# ESP32C5_RADIO register map
Vendor: Espressif; Series: ESP32-C5; File version: 0.1
Registers are 32-bit, read-write, no defined reset value unless marked. A register's access mark holds for its fields unless they carry their own. Offsets are from the block's base; [hi:lo] are bit positions; 'fields as' and 'values as' point back to an identical list.

## MODEM_WIFI_MAC_OBSERVED (part 2 of 2) — Sparse source-qualified word views in the existing owned MMIO aperture; individual meanings and side effects remain unknown.
Base 0x600A4000
0x814 WORD_0814_OPAQUE — Opaque: meaning not established. Aligned 32-bit bus view explicitly addressed by the cited vendor source. No reset or hardware write effect is established.
  [31:0] BITS_0_31_OPAQUE — Opaque: meaning not established. Observed source use; the individual hardware meaning is unknown.
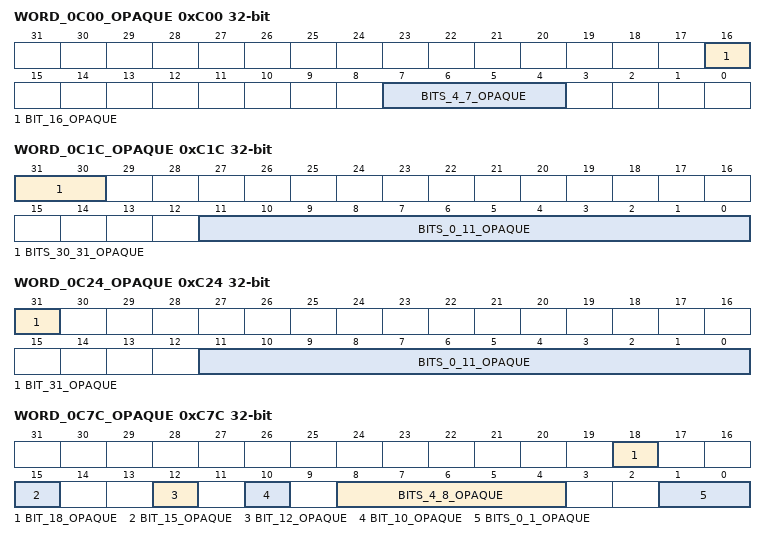
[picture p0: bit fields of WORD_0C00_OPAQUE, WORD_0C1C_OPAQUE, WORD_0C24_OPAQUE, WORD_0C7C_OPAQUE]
0xC00 WORD_0C00_OPAQUE — Opaque: meaning not established. Aligned 32-bit bus view explicitly addressed by the cited vendor source. No reset or hardware write effect is established.
  [16] BIT_16_OPAQUE — Opaque: meaning not established. Observed source use; the individual hardware meaning is unknown.
  [7:4] BITS_4_7_OPAQUE — Opaque: meaning not established. Observed source use; the individual hardware meaning is unknown.
0xC1C WORD_0C1C_OPAQUE — Opaque: meaning not established. Aligned 32-bit bus view explicitly addressed by the cited vendor source. No reset or hardware write effect is established.
  [31:30] BITS_30_31_OPAQUE — Opaque: meaning not established. Observed source use; the individual hardware meaning is unknown.
  [11:0] BITS_0_11_OPAQUE — Opaque: meaning not established. Observed source use; the individual hardware meaning is unknown.
0xC20 WORD_0C20_OPAQUE — Opaque: meaning not established. Aligned 32-bit bus view explicitly addressed by the cited vendor source. No reset or hardware write effect is established.
  [11:0] BITS_0_11_OPAQUE — Opaque: meaning not established. Observed source use; the individual hardware meaning is unknown.
0xC24 WORD_0C24_OPAQUE — Opaque: meaning not established. Aligned 32-bit bus view explicitly addressed by the cited vendor source. No reset or hardware write effect is established.
  [31] BIT_31_OPAQUE — Opaque: meaning not established. Observed source use; the individual hardware meaning is unknown.
  [11:0] BITS_0_11_OPAQUE — Opaque: meaning not established. Observed source use; the individual hardware meaning is unknown.
0xC2C WORD_0C2C_OPAQUE — Opaque: meaning not established. Aligned 32-bit bus view explicitly addressed by the cited vendor source. No reset or hardware write effect is established.
  [12] BIT_12_OPAQUE — Opaque: meaning not established. Observed source use; the individual hardware meaning is unknown.
0xC34 WORD_0C34_OPAQUE ro — Opaque: meaning not established. Aligned 32-bit bus view explicitly addressed by the cited vendor source. No reset or hardware write effect is established.
  fields as WORD_0C2C_OPAQUE
0xC38 WORD_0C38_OPAQUE — Opaque: meaning not established. Aligned 32-bit bus view explicitly addressed by the cited vendor source. No reset or hardware write effect is established.
  fields as WORD_0C2C_OPAQUE
0xC50 WORD_0C50_OPAQUE — Opaque: meaning not established. Aligned 32-bit bus view explicitly addressed by the cited vendor source. No reset or hardware write effect is established.
  [15:0] BITS_0_15_OPAQUE — Opaque: meaning not established. Observed source use; the individual hardware meaning is unknown.
0xC54 WORD_0C54_OPAQUE — Opaque: meaning not established. Aligned 32-bit bus view explicitly addressed by the cited vendor source. No reset or hardware write effect is established.
  [31:10] BITS_10_31_OPAQUE — Opaque: meaning not established. Observed source use; the individual hardware meaning is unknown.
0xC58 WORD_0C58_OPAQUE — Opaque: meaning not established. Aligned 32-bit bus view explicitly addressed by the cited vendor source. No reset or hardware write effect is established.
  fields as WORD_0814_OPAQUE
0xC60 WORD_0C60_OPAQUE — Opaque: meaning not established. Aligned 32-bit bus view explicitly addressed by the cited vendor source. No reset or hardware write effect is established.
  [31:16] BITS_16_31_OPAQUE — Opaque: meaning not established. Observed source use; the individual hardware meaning is unknown.
0xC64 WORD_0C64_OPAQUE ro — Opaque: meaning not established. Aligned 32-bit bus view explicitly addressed by the cited vendor source. No reset or hardware write effect is established.
  fields as WORD_0C60_OPAQUE
0xC70 WORD_0C70_OPAQUE ro — Opaque: meaning not established. Aligned 32-bit bus view explicitly addressed by the cited vendor source. No reset or hardware write effect is established.
  [31:20] BITS_20_31_OPAQUE — Opaque: meaning not established. Observed source use; the individual hardware meaning is unknown.
0xC74 WORD_0C74_OPAQUE ro — Opaque: meaning not established. Aligned 32-bit bus view explicitly addressed by the cited vendor source. No reset or hardware write effect is established.
  [31:28] BITS_28_31_OPAQUE — Opaque: meaning not established. Observed source use; the individual hardware meaning is unknown.
0xC78 WORD_0C78_OPAQUE — Opaque: meaning not established. Aligned 32-bit bus view explicitly addressed by the cited vendor source. No reset or hardware write effect is established.
  fields as WORD_0814_OPAQUE
0xC7C WORD_0C7C_OPAQUE — Opaque: meaning not established. Aligned 32-bit bus view explicitly addressed by the cited vendor source. No reset or hardware write effect is established.
  [18] BIT_18_OPAQUE — Opaque: meaning not established. Observed source use; the individual hardware meaning is unknown.
  [15] BIT_15_OPAQUE — Opaque: meaning not established. Observed source use; the individual hardware meaning is unknown.
  [12] BIT_12_OPAQUE — Opaque: meaning not established. Observed source use; the individual hardware meaning is unknown.
  [10] BIT_10_OPAQUE — Opaque: meaning not established. Observed source use; the individual hardware meaning is unknown.
  [8:4] BITS_4_8_OPAQUE — Opaque: meaning not established. Observed source use; the individual hardware meaning is unknown.
  [1:0] BITS_0_1_OPAQUE — Opaque: meaning not established. Observed source use; the individual hardware meaning is unknown.
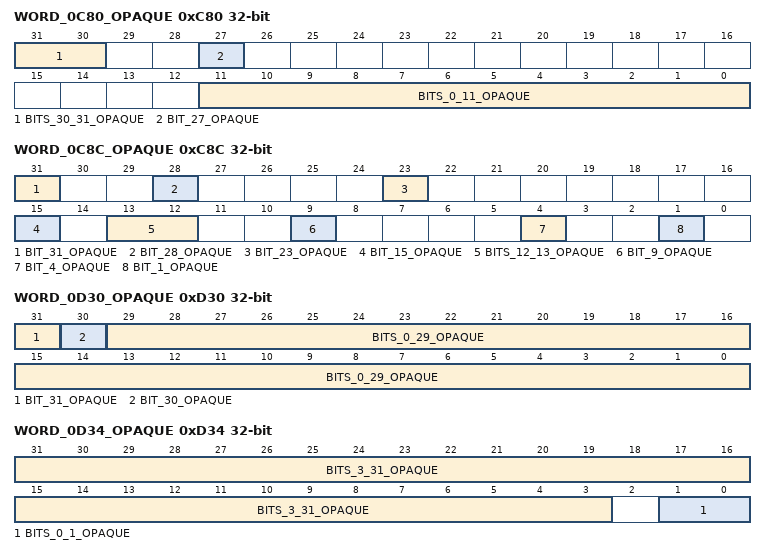
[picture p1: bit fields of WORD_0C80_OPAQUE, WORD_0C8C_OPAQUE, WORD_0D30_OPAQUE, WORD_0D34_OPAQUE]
0xC80 WORD_0C80_OPAQUE — Opaque: meaning not established. Aligned 32-bit bus view explicitly addressed by the cited vendor source. No reset or hardware write effect is established.
  [31:30] BITS_30_31_OPAQUE — Opaque: meaning not established. Observed source use; the individual hardware meaning is unknown.
  [27] BIT_27_OPAQUE — Opaque: meaning not established. Observed source use; the individual hardware meaning is unknown.
  [11:0] BITS_0_11_OPAQUE — Opaque: meaning not established. Observed source use; the individual hardware meaning is unknown.
0xC84 WORD_0C84_OPAQUE — Opaque: meaning not established. Aligned 32-bit bus view explicitly addressed by the cited vendor source. No reset or hardware write effect is established.
  [31:18] BITS_18_31_OPAQUE — Opaque: meaning not established. Observed source use; the individual hardware meaning is unknown.
0xC88 WORD_0C88_OPAQUE — Opaque: meaning not established. Aligned 32-bit bus view explicitly addressed by the cited vendor source. No reset or hardware write effect is established.
  [1:0] BITS_0_1_OPAQUE — Opaque: meaning not established. Observed source use; the individual hardware meaning is unknown.
0xC8C WORD_0C8C_OPAQUE — Opaque: meaning not established. Aligned 32-bit bus view explicitly addressed by the cited vendor source. No reset or hardware write effect is established.
  [31] BIT_31_OPAQUE — Opaque: meaning not established. Observed source use; the individual hardware meaning is unknown.
  [28] BIT_28_OPAQUE — Opaque: meaning not established. Observed source use; the individual hardware meaning is unknown.
  [23] BIT_23_OPAQUE — Opaque: meaning not established. Observed source use; the individual hardware meaning is unknown.
  [15] BIT_15_OPAQUE — Opaque: meaning not established. Observed source use; the individual hardware meaning is unknown.
  [13:12] BITS_12_13_OPAQUE — Opaque: meaning not established. Observed source use; the individual hardware meaning is unknown.
  [9] BIT_9_OPAQUE — Opaque: meaning not established. Observed source use; the individual hardware meaning is unknown.
  [4] BIT_4_OPAQUE — Opaque: meaning not established. Observed source use; the individual hardware meaning is unknown.
  [1] BIT_1_OPAQUE — Opaque: meaning not established. Observed source use; the individual hardware meaning is unknown.
0xC90 WORD_0C90_OPAQUE — Opaque: meaning not established. Aligned 32-bit bus view explicitly addressed by the cited vendor source. No reset or hardware write effect is established.
  fields as WORD_0814_OPAQUE
0xC94 WORD_0C94_OPAQUE — Opaque: meaning not established. Aligned source-qualified 32-bit bus view in the existing owned aperture. No reset, safe transaction or read safety is established.
  [7:0] BITS_0_7_OPAQUE — Opaque: meaning not established. Observed source use; the individual hardware meaning is unknown.
0xC98 WORD_0C98_OPAQUE — Opaque: meaning not established. Aligned 32-bit bus view explicitly addressed by the cited vendor source. No reset or hardware write effect is established.
  [3:2] BITS_2_3_OPAQUE — Opaque: meaning not established. Observed source use; the individual hardware meaning is unknown.
0xC9C WORD_0C9C_OPAQUE — Opaque: meaning not established. Aligned 32-bit bus view explicitly addressed by the cited vendor source. No reset or hardware write effect is established.
  fields as WORD_0814_OPAQUE
0xCA0 WORD_0CA0_OPAQUE — Opaque: meaning not established. Aligned 32-bit bus view explicitly addressed by the cited vendor source. No reset or hardware write effect is established.
  fields as WORD_0814_OPAQUE
0xCA4 WORD_0CA4_OPAQUE — Opaque: meaning not established. Aligned 32-bit bus view explicitly addressed by the cited vendor source. No reset or hardware write effect is established.
  fields as WORD_0C94_OPAQUE
0xCA8 WORD_0CA8_OPAQUE — Opaque: meaning not established. Aligned 32-bit bus view explicitly addressed by the cited vendor source. No reset or hardware write effect is established.
  fields as WORD_0814_OPAQUE
0xCBC WORD_0CBC_OPAQUE — Opaque: meaning not established. Aligned 32-bit bus view explicitly addressed by the cited vendor source. No reset or hardware write effect is established.
  [31] BIT_31_OPAQUE — Opaque: meaning not established. Observed source use; the individual hardware meaning is unknown.
0xCC4 WORD_0CC4_OPAQUE — Opaque: meaning not established. Aligned source-qualified 32-bit bus view in the existing owned aperture. No reset, safe transaction or read safety is established.
  [2] BIT_2_OPAQUE — Opaque: meaning not established. Observed source use; the individual hardware meaning is unknown.
0xCD4 WORD_0CD4_OPAQUE — Opaque: meaning not established. Aligned 32-bit bus view explicitly addressed by the cited vendor source. No reset or hardware write effect is established.
  fields as WORD_0CC4_OPAQUE
0xCE4 WORD_0CE4_OPAQUE — Opaque: meaning not established. Aligned 32-bit bus view explicitly addressed by the cited vendor source. No reset or hardware write effect is established.
  fields as WORD_0CC4_OPAQUE
0xCF8 WORD_0CF8_OPAQUE ro — Opaque: meaning not established. Aligned 32-bit bus view explicitly addressed by the cited vendor source. No reset or hardware write effect is established.
  fields as WORD_0814_OPAQUE
0xD08 WORD_0D08_OPAQUE ro — Opaque: meaning not established. Aligned 32-bit bus view explicitly addressed by the cited vendor source. No reset or hardware write effect is established.
  fields as WORD_0814_OPAQUE
0xD18 WORD_0D18_OPAQUE ro — Opaque: meaning not established. Aligned 32-bit bus view explicitly addressed by the cited vendor source. No reset or hardware write effect is established.
  fields as WORD_0814_OPAQUE
0xD28 WORD_0D28_OPAQUE ro — Opaque: meaning not established. Aligned 32-bit bus view explicitly addressed by the cited vendor source. No reset or hardware write effect is established.
  fields as WORD_0814_OPAQUE
0xD30 WORD_0D30_OPAQUE — Opaque: meaning not established. Aligned 32-bit bus view explicitly addressed by the cited vendor source. No reset or hardware write effect is established.
  [31] BIT_31_OPAQUE — Opaque: meaning not established. Observed source use; the individual hardware meaning is unknown.
  [30] BIT_30_OPAQUE — Opaque: meaning not established. Observed source use; the individual hardware meaning is unknown.
  [29:0] BITS_0_29_OPAQUE — Opaque: meaning not established. Observed source use; the individual hardware meaning is unknown.
0xD34 WORD_0D34_OPAQUE — Opaque: meaning not established. Aligned 32-bit bus view explicitly addressed by the cited vendor source. No reset or hardware write effect is established.
  [31:3] BITS_3_31_OPAQUE — Opaque: meaning not established. Observed source use; the individual hardware meaning is unknown.
  [1:0] BITS_0_1_OPAQUE — Opaque: meaning not established. Observed source use; the individual hardware meaning is unknown.
0xD38 WORD_0D38_OPAQUE ro — Opaque: meaning not established. Aligned 32-bit bus view explicitly addressed by the cited vendor source. No reset or hardware write effect is established.
  fields as WORD_0814_OPAQUE
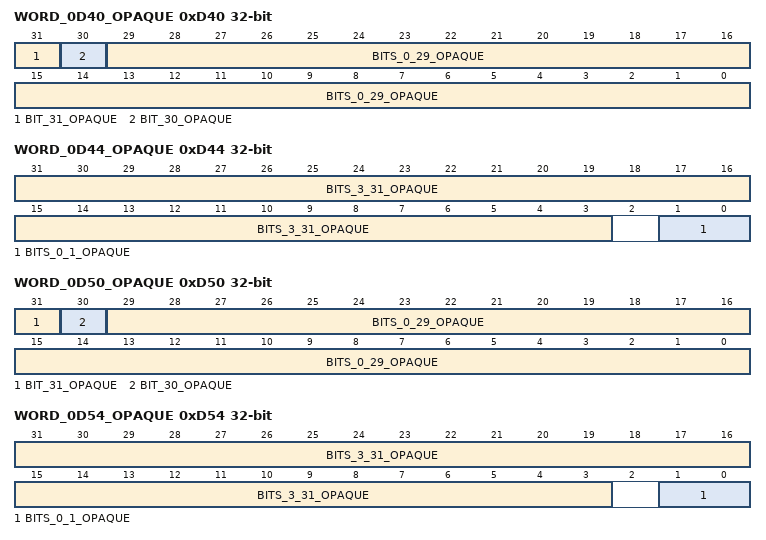
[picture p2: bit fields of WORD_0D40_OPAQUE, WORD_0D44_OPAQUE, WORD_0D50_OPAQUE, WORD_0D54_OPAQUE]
0xD40 WORD_0D40_OPAQUE — Opaque: meaning not established. Aligned 32-bit bus view explicitly addressed by the cited vendor source. No reset or hardware write effect is established.
  fields as WORD_0D30_OPAQUE
0xD44 WORD_0D44_OPAQUE — Opaque: meaning not established. Aligned 32-bit bus view explicitly addressed by the cited vendor source. No reset or hardware write effect is established.
  fields as WORD_0D34_OPAQUE
0xD48 WORD_0D48_OPAQUE ro — Opaque: meaning not established. Aligned 32-bit bus view explicitly addressed by the cited vendor source. No reset or hardware write effect is established.
  fields as WORD_0814_OPAQUE
0xD50 WORD_0D50_OPAQUE — Opaque: meaning not established. Aligned 32-bit bus view explicitly addressed by the cited vendor source. No reset or hardware write effect is established.
  fields as WORD_0D30_OPAQUE
0xD54 WORD_0D54_OPAQUE — Opaque: meaning not established. Aligned 32-bit bus view explicitly addressed by the cited vendor source. No reset or hardware write effect is established.
  fields as WORD_0D34_OPAQUE
0xD58 WORD_0D58_OPAQUE ro — Opaque: meaning not established. Aligned 32-bit bus view explicitly addressed by the cited vendor source. No reset or hardware write effect is established.
  fields as WORD_0814_OPAQUE
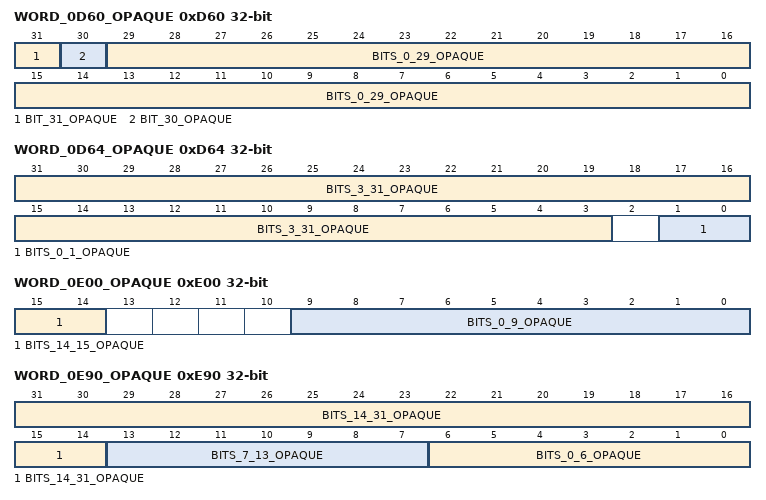
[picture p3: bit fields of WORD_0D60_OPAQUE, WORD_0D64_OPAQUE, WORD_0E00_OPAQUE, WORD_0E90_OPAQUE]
0xD60 WORD_0D60_OPAQUE — Opaque: meaning not established. Aligned 32-bit bus view explicitly addressed by the cited vendor source. No reset or hardware write effect is established.
  fields as WORD_0D30_OPAQUE
0xD64 WORD_0D64_OPAQUE — Opaque: meaning not established. Aligned 32-bit bus view explicitly addressed by the cited vendor source. No reset or hardware write effect is established.
  fields as WORD_0D34_OPAQUE
0xD68 WORD_0D68_OPAQUE — Opaque: meaning not established. Aligned 32-bit bus view explicitly addressed by the cited vendor source. No reset or hardware write effect is established.
  fields as WORD_0814_OPAQUE
0xD74 WORD_0D74_OPAQUE — Opaque: meaning not established. Aligned source-qualified 32-bit bus view in the existing owned aperture. No reset, safe transaction or read safety is established.
  [19:0] BITS_0_19_OPAQUE — Opaque: meaning not established. Observed source use; the individual hardware meaning is unknown.
0xD7C WORD_0D7C_OPAQUE — Opaque: meaning not established. Aligned source-qualified 32-bit bus view in the existing owned aperture. No reset, safe transaction or read safety is established.
  fields as WORD_0D74_OPAQUE
0xD84 WORD_0D84_OPAQUE — Opaque: meaning not established. Aligned source-qualified 32-bit bus view in the existing owned aperture. No reset, safe transaction or read safety is established.
  fields as WORD_0D74_OPAQUE
0xD8C WORD_0D8C_OPAQUE — Opaque: meaning not established. Aligned source-qualified 32-bit bus view in the existing owned aperture. No reset, safe transaction or read safety is established.
  fields as WORD_0D74_OPAQUE
0xDB4 WORD_0DB4_OPAQUE — Opaque: meaning not established. Aligned 32-bit bus view explicitly addressed by the cited vendor source. No reset or hardware write effect is established.
  fields as WORD_0814_OPAQUE
0xDB8 WORD_0DB8_OPAQUE — Opaque: meaning not established. Aligned 32-bit bus view explicitly addressed by the cited vendor source. No reset or hardware write effect is established.
  fields as WORD_0814_OPAQUE
0xDBC WORD_0DBC_OPAQUE — Opaque: meaning not established. Aligned 32-bit bus view explicitly addressed by the cited vendor source. No reset or hardware write effect is established.
  fields as WORD_0814_OPAQUE
0xDC0 WORD_0DC0_OPAQUE — Opaque: meaning not established. Aligned 32-bit bus view explicitly addressed by the cited vendor source. No reset or hardware write effect is established.
  fields as WORD_0814_OPAQUE
0xDC4 WORD_0DC4_OPAQUE — Opaque: meaning not established. Aligned 32-bit bus view explicitly addressed by the cited vendor source. No reset or hardware write effect is established.
  fields as WORD_0814_OPAQUE
0xDD0 WORD_0DD0_OPAQUE — Opaque: meaning not established. Aligned 32-bit bus view explicitly addressed by the cited vendor source. No reset or hardware write effect is established.
  fields as WORD_0814_OPAQUE
0xDD4 WORD_0DD4_OPAQUE — Opaque: meaning not established. Aligned 32-bit bus view explicitly addressed by the cited vendor source. No reset or hardware write effect is established.
  fields as WORD_0814_OPAQUE
0xDD8 WORD_0DD8_OPAQUE — Opaque: meaning not established. Aligned 32-bit bus view explicitly addressed by the cited vendor source. No reset or hardware write effect is established.
  [5:0] BITS_0_5_OPAQUE — Opaque: meaning not established. Observed source use; the individual hardware meaning is unknown.
0xDDC WORD_0DDC_OPAQUE — Opaque: meaning not established. Aligned 32-bit bus view explicitly addressed by the cited vendor source. No reset or hardware write effect is established.
  fields as WORD_0C88_OPAQUE
0xDE0 WORD_0DE0_OPAQUE — Opaque: meaning not established. Aligned 32-bit bus view explicitly addressed by the cited vendor source. No reset or hardware write effect is established.
  fields as WORD_0C70_OPAQUE
0xDEC WORD_0DEC_OPAQUE — Opaque: meaning not established. Aligned source-qualified 32-bit bus view in the existing owned aperture. No reset, safe transaction or read safety is established.
  [0] BIT_0_OPAQUE — Opaque: meaning not established. Observed source use; the individual hardware meaning is unknown.
0xDF0 WORD_0DF0_OPAQUE — Opaque: meaning not established. Aligned 32-bit bus view explicitly addressed by the cited vendor source. No reset or hardware write effect is established.
  fields as WORD_0814_OPAQUE
0xDF4 WORD_0DF4_OPAQUE — Opaque: meaning not established. Aligned source-qualified 32-bit bus view in the existing owned aperture. No reset, safe transaction or read safety is established.
  fields as WORD_0DEC_OPAQUE
0xDF8 WORD_0DF8_OPAQUE — Opaque: meaning not established. Aligned 32-bit bus view explicitly addressed by the cited vendor source. No reset or hardware write effect is established.
  fields as WORD_0814_OPAQUE
0xDFC WORD_0DFC_OPAQUE — Opaque: meaning not established. Aligned 32-bit bus view explicitly addressed by the cited vendor source. No reset or hardware write effect is established.
  fields as WORD_0814_OPAQUE
0xE00 WORD_0E00_OPAQUE — Opaque: meaning not established. Aligned 32-bit bus view explicitly addressed by the cited vendor source. No reset or hardware write effect is established.
  [15:14] BITS_14_15_OPAQUE — Opaque: meaning not established. Observed source use; the individual hardware meaning is unknown.
  [9:0] BITS_0_9_OPAQUE — Opaque: meaning not established. Observed source use; the individual hardware meaning is unknown.
0xE14 WORD_0E14_OPAQUE ro — Opaque: meaning not established. Aligned 32-bit bus view explicitly addressed by the cited vendor source. No reset or hardware write effect is established.
  fields as WORD_0814_OPAQUE
0xE18 WORD_0E18_OPAQUE ro — Opaque: meaning not established. Aligned 32-bit bus view explicitly addressed by the cited vendor source. No reset or hardware write effect is established.
  fields as WORD_0814_OPAQUE
0xE1C WORD_0E1C_OPAQUE ro — Opaque: meaning not established. Aligned 32-bit bus view explicitly addressed by the cited vendor source. No reset or hardware write effect is established.
  fields as WORD_0814_OPAQUE
0xE24 WORD_0E24_OPAQUE — Opaque: meaning not established. Aligned 32-bit bus view explicitly addressed by the cited vendor source. No reset or hardware write effect is established.
  fields as WORD_0CBC_OPAQUE
0xE2C WORD_0E2C_OPAQUE ro — Opaque: meaning not established. Aligned 32-bit bus view explicitly addressed by the cited vendor source. No reset or hardware write effect is established.
  fields as WORD_0814_OPAQUE
0xE30 WORD_0E30_OPAQUE ro — Opaque: meaning not established. Aligned 32-bit bus view explicitly addressed by the cited vendor source. No reset or hardware write effect is established.
  fields as WORD_0814_OPAQUE
0xE38 WORD_0E38_OPAQUE — Opaque: meaning not established. Aligned 32-bit bus view explicitly addressed by the cited vendor source. No reset or hardware write effect is established.
  [8:0] BITS_0_8_OPAQUE — Opaque: meaning not established. Observed source use; the individual hardware meaning is unknown.
0xE8C WORD_0E8C_OPAQUE ro — Opaque: meaning not established. Aligned 32-bit bus view explicitly addressed by the cited vendor source. No reset or hardware write effect is established.
  fields as WORD_0814_OPAQUE
0xE90 WORD_0E90_OPAQUE ro — Opaque: meaning not established. Aligned 32-bit bus view explicitly addressed by the cited vendor source. No reset or hardware write effect is established.
  [31:14] BITS_14_31_OPAQUE — Opaque: meaning not established. Observed source use; the individual hardware meaning is unknown.
  [13:7] BITS_7_13_OPAQUE — Opaque: meaning not established. Observed source use; the individual hardware meaning is unknown.
  [6:0] BITS_0_6_OPAQUE — Opaque: meaning not established. Observed source use; the individual hardware meaning is unknown.
0xE94 WORD_0E94_OPAQUE ro — Opaque: meaning not established. Aligned 32-bit bus view explicitly addressed by the cited vendor source. No reset or hardware write effect is established.
  fields as WORD_0814_OPAQUE
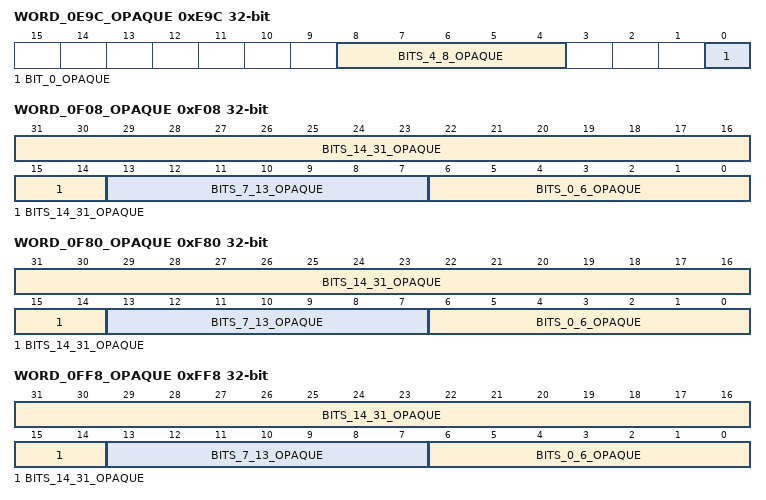
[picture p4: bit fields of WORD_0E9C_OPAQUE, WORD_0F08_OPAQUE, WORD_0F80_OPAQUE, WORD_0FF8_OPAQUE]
0xE9C WORD_0E9C_OPAQUE — Opaque: meaning not established. Aligned 32-bit bus view explicitly addressed by the cited vendor source. No reset or hardware write effect is established.
  [8:4] BITS_4_8_OPAQUE — Opaque: meaning not established. Observed source use; the individual hardware meaning is unknown.
  [0] BIT_0_OPAQUE — Opaque: meaning not established. Observed source use; the individual hardware meaning is unknown.
0xEA0 WORD_0EA0_OPAQUE — Opaque: meaning not established. Aligned 32-bit bus view explicitly addressed by the cited vendor source. No reset or hardware write effect is established.
  [31:5] BITS_5_31_OPAQUE — Opaque: meaning not established. Observed source use; the individual hardware meaning is unknown.
0xEA4 WORD_0EA4_OPAQUE — Opaque: meaning not established. Aligned 32-bit bus view explicitly addressed by the cited vendor source. No reset or hardware write effect is established.
  [24:18] BITS_18_24_OPAQUE — Opaque: meaning not established. Observed source use; the individual hardware meaning is unknown.
0xEAC WORD_0EAC_OPAQUE — Opaque: meaning not established. Aligned 32-bit bus view explicitly addressed by the cited vendor source. No reset or hardware write effect is established.
  fields as WORD_0C20_OPAQUE
0xF04 WORD_0F04_OPAQUE ro — Opaque: meaning not established. Aligned 32-bit bus view explicitly addressed by the cited vendor source. No reset or hardware write effect is established.
  fields as WORD_0814_OPAQUE
0xF08 WORD_0F08_OPAQUE ro — Opaque: meaning not established. Aligned 32-bit bus view explicitly addressed by the cited vendor source. No reset or hardware write effect is established.
  fields as WORD_0E90_OPAQUE
0xF0C WORD_0F0C_OPAQUE ro — Opaque: meaning not established. Aligned 32-bit bus view explicitly addressed by the cited vendor source. No reset or hardware write effect is established.
  fields as WORD_0814_OPAQUE
0xF7C WORD_0F7C_OPAQUE ro — Opaque: meaning not established. Aligned 32-bit bus view explicitly addressed by the cited vendor source. No reset or hardware write effect is established.
  fields as WORD_0814_OPAQUE
0xF80 WORD_0F80_OPAQUE ro — Opaque: meaning not established. Aligned 32-bit bus view explicitly addressed by the cited vendor source. No reset or hardware write effect is established.
  fields as WORD_0E90_OPAQUE
0xF84 WORD_0F84_OPAQUE ro — Opaque: meaning not established. Aligned 32-bit bus view explicitly addressed by the cited vendor source. No reset or hardware write effect is established.
  fields as WORD_0814_OPAQUE
0xFF4 WORD_0FF4_OPAQUE ro — Opaque: meaning not established. Aligned 32-bit bus view explicitly addressed by the cited vendor source. No reset or hardware write effect is established.
  fields as WORD_0814_OPAQUE
0xFF8 WORD_0FF8_OPAQUE ro — Opaque: meaning not established. Aligned 32-bit bus view explicitly addressed by the cited vendor source. No reset or hardware write effect is established.
  fields as WORD_0E90_OPAQUE
0xFFC WORD_0FFC_OPAQUE ro — Opaque: meaning not established. Aligned 32-bit bus view explicitly addressed by the cited vendor source. No reset or hardware write effect is established.
  fields as WORD_0814_OPAQUE
0x106C WORD_106C_OPAQUE ro — Opaque: meaning not established. Aligned 32-bit bus view explicitly addressed by the cited vendor source. No reset or hardware write effect is established.
  fields as WORD_0814_OPAQUE
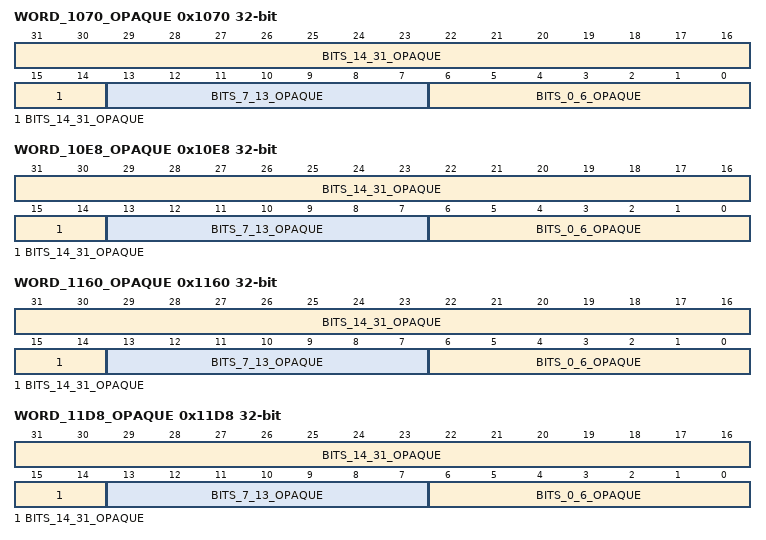
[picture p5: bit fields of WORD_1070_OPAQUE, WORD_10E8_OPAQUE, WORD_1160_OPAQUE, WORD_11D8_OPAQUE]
0x1070 WORD_1070_OPAQUE ro — Opaque: meaning not established. Aligned 32-bit bus view explicitly addressed by the cited vendor source. No reset or hardware write effect is established.
  fields as WORD_0E90_OPAQUE
0x1074 WORD_1074_OPAQUE ro — Opaque: meaning not established. Aligned 32-bit bus view explicitly addressed by the cited vendor source. No reset or hardware write effect is established.
  fields as WORD_0814_OPAQUE
0x10E4 WORD_10E4_OPAQUE ro — Opaque: meaning not established. Aligned 32-bit bus view explicitly addressed by the cited vendor source. No reset or hardware write effect is established.
  fields as WORD_0814_OPAQUE
0x10E8 WORD_10E8_OPAQUE ro — Opaque: meaning not established. Aligned 32-bit bus view explicitly addressed by the cited vendor source. No reset or hardware write effect is established.
  fields as WORD_0E90_OPAQUE
0x10EC WORD_10EC_OPAQUE ro — Opaque: meaning not established. Aligned 32-bit bus view explicitly addressed by the cited vendor source. No reset or hardware write effect is established.
  fields as WORD_0814_OPAQUE
0x115C WORD_115C_OPAQUE ro — Opaque: meaning not established. Aligned 32-bit bus view explicitly addressed by the cited vendor source. No reset or hardware write effect is established.
  fields as WORD_0814_OPAQUE
0x1160 WORD_1160_OPAQUE ro — Opaque: meaning not established. Aligned 32-bit bus view explicitly addressed by the cited vendor source. No reset or hardware write effect is established.
  fields as WORD_0E90_OPAQUE
0x1164 WORD_1164_OPAQUE ro — Opaque: meaning not established. Aligned 32-bit bus view explicitly addressed by the cited vendor source. No reset or hardware write effect is established.
  fields as WORD_0814_OPAQUE
0x11D4 WORD_11D4_OPAQUE ro — Opaque: meaning not established. Aligned 32-bit bus view explicitly addressed by the cited vendor source. No reset or hardware write effect is established.
  fields as WORD_0814_OPAQUE
0x11D8 WORD_11D8_OPAQUE ro — Opaque: meaning not established. Aligned 32-bit bus view explicitly addressed by the cited vendor source. No reset or hardware write effect is established.
  fields as WORD_0E90_OPAQUE
0x11DC WORD_11DC_OPAQUE ro — Opaque: meaning not established. Aligned 32-bit bus view explicitly addressed by the cited vendor source. No reset or hardware write effect is established.
  fields as WORD_0814_OPAQUE
0x124C WORD_124C_OPAQUE ro — Opaque: meaning not established. Aligned 32-bit bus view explicitly addressed by the cited vendor source. No reset or hardware write effect is established.
  fields as WORD_0814_OPAQUE
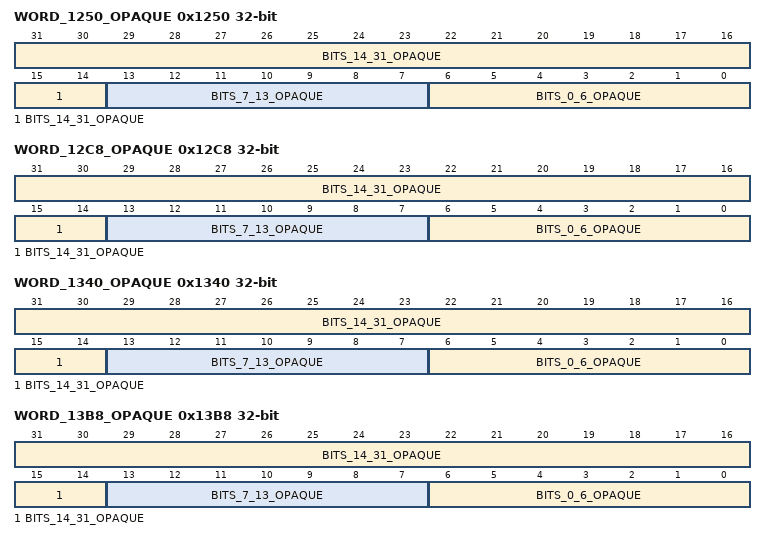
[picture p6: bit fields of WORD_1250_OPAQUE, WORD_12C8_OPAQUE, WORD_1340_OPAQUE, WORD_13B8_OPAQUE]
0x1250 WORD_1250_OPAQUE ro — Opaque: meaning not established. Aligned 32-bit bus view explicitly addressed by the cited vendor source. No reset or hardware write effect is established.
  fields as WORD_0E90_OPAQUE
0x1254 WORD_1254_OPAQUE ro — Opaque: meaning not established. Aligned 32-bit bus view explicitly addressed by the cited vendor source. No reset or hardware write effect is established.
  fields as WORD_0814_OPAQUE
0x12C4 WORD_12C4_OPAQUE ro — Opaque: meaning not established. Aligned 32-bit bus view explicitly addressed by the cited vendor source. No reset or hardware write effect is established.
  fields as WORD_0814_OPAQUE
0x12C8 WORD_12C8_OPAQUE ro — Opaque: meaning not established. Aligned 32-bit bus view explicitly addressed by the cited vendor source. No reset or hardware write effect is established.
  fields as WORD_0E90_OPAQUE
0x12CC WORD_12CC_OPAQUE ro — Opaque: meaning not established. Aligned 32-bit bus view explicitly addressed by the cited vendor source. No reset or hardware write effect is established.
  fields as WORD_0814_OPAQUE
0x133C WORD_133C_OPAQUE ro — Opaque: meaning not established. Aligned 32-bit bus view explicitly addressed by the cited vendor source. No reset or hardware write effect is established.
  fields as WORD_0814_OPAQUE
0x1340 WORD_1340_OPAQUE ro — Opaque: meaning not established. Aligned 32-bit bus view explicitly addressed by the cited vendor source. No reset or hardware write effect is established.
  fields as WORD_0E90_OPAQUE
0x1344 WORD_1344_OPAQUE ro — Opaque: meaning not established. Aligned 32-bit bus view explicitly addressed by the cited vendor source. No reset or hardware write effect is established.
  fields as WORD_0814_OPAQUE
0x134C WORD_134C_OPAQUE — Opaque: meaning not established. Aligned 32-bit bus view explicitly addressed by the cited vendor source. No reset or hardware write effect is established.
  [17] BIT_17_OPAQUE — Opaque: meaning not established. Observed source use; the individual hardware meaning is unknown.
0x13B4 WORD_13B4_OPAQUE ro — Opaque: meaning not established. Aligned 32-bit bus view explicitly addressed by the cited vendor source. No reset or hardware write effect is established.
  fields as WORD_0814_OPAQUE
0x13B8 WORD_13B8_OPAQUE ro — Opaque: meaning not established. Aligned 32-bit bus view explicitly addressed by the cited vendor source. No reset or hardware write effect is established.
  fields as WORD_0E90_OPAQUE
0x13BC WORD_13BC_OPAQUE ro — Opaque: meaning not established. Aligned 32-bit bus view explicitly addressed by the cited vendor source. No reset or hardware write effect is established.
  fields as WORD_0814_OPAQUE
0x13C4 WORD_13C4_OPAQUE — Opaque: meaning not established. Aligned 32-bit bus view explicitly addressed by the cited vendor source. No reset or hardware write effect is established.
  fields as WORD_134C_OPAQUE
0x142C WORD_142C_OPAQUE ro — Opaque: meaning not established. Aligned 32-bit bus view explicitly addressed by the cited vendor source. No reset or hardware write effect is established.
  fields as WORD_0814_OPAQUE
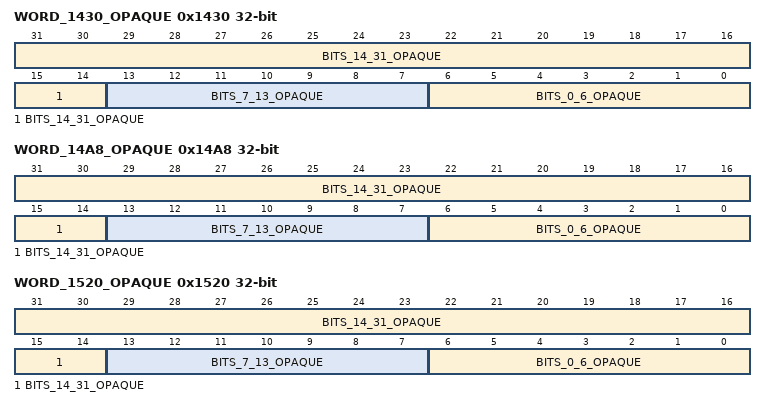
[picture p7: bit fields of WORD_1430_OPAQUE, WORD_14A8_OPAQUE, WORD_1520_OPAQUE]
0x1430 WORD_1430_OPAQUE ro — Opaque: meaning not established. Aligned 32-bit bus view explicitly addressed by the cited vendor source. No reset or hardware write effect is established.
  fields as WORD_0E90_OPAQUE
0x1434 WORD_1434_OPAQUE ro — Opaque: meaning not established. Aligned 32-bit bus view explicitly addressed by the cited vendor source. No reset or hardware write effect is established.
  fields as WORD_0814_OPAQUE
0x143C WORD_143C_OPAQUE — Opaque: meaning not established. Aligned 32-bit bus view explicitly addressed by the cited vendor source. No reset or hardware write effect is established.
  fields as WORD_134C_OPAQUE
0x14A4 WORD_14A4_OPAQUE ro — Opaque: meaning not established. Aligned 32-bit bus view explicitly addressed by the cited vendor source. No reset or hardware write effect is established.
  fields as WORD_0814_OPAQUE
0x14A8 WORD_14A8_OPAQUE ro — Opaque: meaning not established. Aligned 32-bit bus view explicitly addressed by the cited vendor source. No reset or hardware write effect is established.
  fields as WORD_0E90_OPAQUE
0x14AC WORD_14AC_OPAQUE ro — Opaque: meaning not established. Aligned 32-bit bus view explicitly addressed by the cited vendor source. No reset or hardware write effect is established.
  fields as WORD_0814_OPAQUE
0x14B4 WORD_14B4_OPAQUE — Opaque: meaning not established. Aligned 32-bit bus view explicitly addressed by the cited vendor source. No reset or hardware write effect is established.
  fields as WORD_134C_OPAQUE
0x14C8 WORD_14C8_OPAQUE — Opaque: meaning not established. Aligned 32-bit bus view explicitly addressed by the cited vendor source. No reset or hardware write effect is established.
  [24:2] BITS_2_24_OPAQUE — Opaque: meaning not established. Observed source use; the individual hardware meaning is unknown.
0x14D0 WORD_14D0_OPAQUE — Opaque: meaning not established. Aligned 32-bit bus view explicitly addressed by the cited vendor source. No reset or hardware write effect is established.
  [27:11] BITS_11_27_OPAQUE — Opaque: meaning not established. Observed source use; the individual hardware meaning is unknown.
0x14D8 WORD_14D8_OPAQUE — Opaque: meaning not established. Aligned 32-bit bus view explicitly addressed by the cited vendor source. No reset or hardware write effect is established.
  fields as WORD_0814_OPAQUE
0x14E4 WORD_14E4_OPAQUE — Opaque: meaning not established. Aligned 32-bit bus view explicitly addressed by the cited vendor source. No reset or hardware write effect is established.
  [18:0] BITS_0_18_OPAQUE — Opaque: meaning not established. Observed source use; the individual hardware meaning is unknown.
0x1514 WORD_1514_OPAQUE ro — Opaque: meaning not established. Aligned 32-bit bus view explicitly addressed by the cited vendor source. No reset or hardware write effect is established.
  fields as WORD_0814_OPAQUE
0x151C WORD_151C_OPAQUE ro — Opaque: meaning not established. Aligned 32-bit bus view explicitly addressed by the cited vendor source. No reset or hardware write effect is established.
  fields as WORD_0814_OPAQUE
0x1520 WORD_1520_OPAQUE ro — Opaque: meaning not established. Aligned 32-bit bus view explicitly addressed by the cited vendor source. No reset or hardware write effect is established.
  fields as WORD_0E90_OPAQUE
0x1524 WORD_1524_OPAQUE ro — Opaque: meaning not established. Aligned 32-bit bus view explicitly addressed by the cited vendor source. No reset or hardware write effect is established.
  fields as WORD_0814_OPAQUE
0x182C WORD_182C_OPAQUE ro — Opaque: meaning not established. Aligned 32-bit bus view explicitly addressed by the cited vendor source. No reset or hardware write effect is established.
  [31:30] BITS_30_31_OPAQUE — Opaque: meaning not established. Observed source use; the individual hardware meaning is unknown.
0x1C00 WORD_1C00_OPAQUE ro — Opaque: meaning not established. Aligned 32-bit bus view explicitly addressed by the cited vendor source. No reset or hardware write effect is established.
  fields as WORD_0C50_OPAQUE
0x1F94 WORD_1F94_OPAQUE ro — Opaque: meaning not established. Aligned 32-bit bus view explicitly addressed by the cited vendor source. No reset or hardware write effect is established.
  fields as WORD_0C94_OPAQUE
